# PIC32CK1025GC00064 device description
Architecture: CORTEX-M33; Family: PIC32CK; Series: PIC32CKGC00
Registers are 32-bit, read-write, reset 0x0 unless marked. A register's access mark holds for its fields unless they carry their own. Offsets are from the block's base; [hi:lo] are bit positions; lines under a group give offsets from that group; {n}, {i} and the like mark numbered series; <NAME> marks a mode.

## DWT — Data Watchpoint and Trace
Instances: DWT 0xE0001000
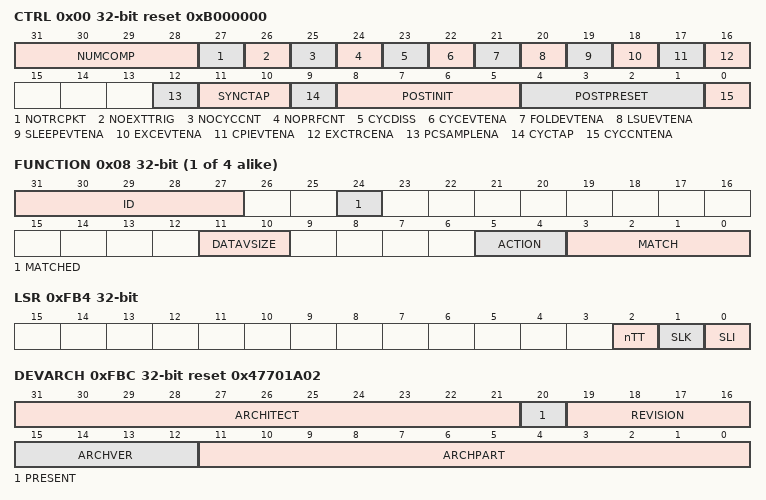
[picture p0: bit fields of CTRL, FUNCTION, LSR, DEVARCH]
0x00 CTRL reset 0xB000000 — DWT Control Register
  [31:28] NUMCOMP — Number of comparators
  [27] NOTRCPKT — No trace packets
  [26] NOEXTTRIG — No external triggers
  [25] NOCYCCNT — No cycle count
  [24] NOPRFCNT — No profile counters
  [23] CYCDISS — Cycle counter disabled secure
  [22] CYCEVTENA — Cycle event enable
  [21] FOLDEVTENA — Fold event enable
  [20] LSUEVTENA — LSU event enable
  [19] SLEEPEVTENA — Sleep event enable
  [18] EXCEVTENA — Exception event enable
  [17] CPIEVTENA — CPI event enable
  [16] EXCTRCENA — Exception trace enable
  [12] PCSAMPLENA — PC sample enable
  [11:10] SYNCTAP — Synchronization tap
  [9] CYCTAP — Cycle count tap
  [8:5] POSTINIT — POSTCNT initial
  [4:1] POSTPRESET — POSTCNT preset
  [0] CYCCNTENA — CYCCNT enable
0x04 CYCCNT reset not defined — DWT Cycle Count Register
  [31:0] CYCCNT — Incrementing cycle counter value
0x08 CPICNT reset not defined — DWT CPI Count Register
  [7:0] CPICNT — Base instruction overhead counter
0x0C EXCCNT reset not defined — DWT Exception Overhead Count Register
  [7:0] EXCCNT — Exception overhead counter
0x10 SLEEPCNT reset not defined — DWT Sleep Count Register
  [7:0] SLEEPCNT — Sleep counter
0x14 LSUCNT reset not defined — DWT LSU Count Register
  [7:0] LSUCNT — Load-store overhead counter
0x18 FOLDCNT reset not defined — DWT Folded Instruction Count Register
  [7:0] FOLDCNT — Folded instruction counter
0x1C PCSR ro reset not defined — DWT Program Counter Sample Register
  [31:0] EIASAMPLE — Executed instruction address sample
{0x20+0x10*i} COMPARATOR[{i}] (i=0..3) group
  0x00 COMP reset not defined — DWT Comparator Register n
    [31:0] VALUE — Cycle/PC/data value or data address
  0x08 FUNCTION reset not defined — DWT Function Register x
    [31:27] ID — Identify capability
    [24] MATCHED — Comparator matched
    [11:10] DATAVSIZE — Data value size
    [5:4] ACTION — Action on match
    [3:0] MATCH — Match type
0xFB0 LAR wo reset not defined — DWT Software Lock Access Register
  [31:0] KEY — Lock access control
    0xC5ACCE55=UNLOCK (Unlock key value)
0xFB4 LSR ro reset not defined — DWT Software Lock Status Register
  [2] nTT — Not thirty-two bit
  [1] SLK — Software Lock status
  [0] SLI — Software Lock implemented
0xFBC DEVARCH ro reset 0x47701A02 — DWT Device Architecture Register
  [31:21] ARCHITECT
  [20] PRESENT — DEVARCH Present
  [19:16] REVISION
  [15:12] ARCHVER — Architecture Version
  [11:0] ARCHPART — Architecture Part
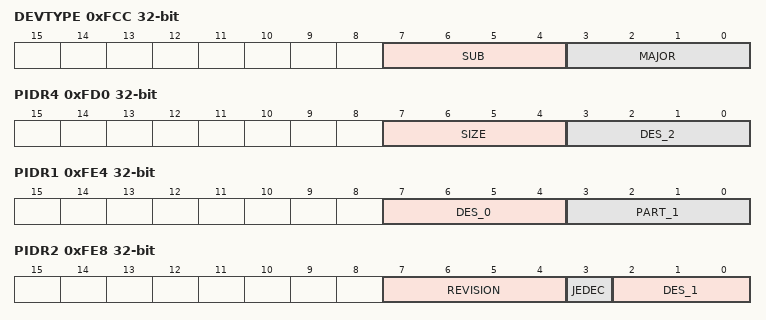
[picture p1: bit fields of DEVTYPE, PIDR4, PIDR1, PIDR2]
0xFCC DEVTYPE ro — DWT Device Type Register
  [7:4] SUB — Sub-type
  [3:0] MAJOR — Major type
0xFD0 PIDR4 ro reset not defined — DWT Peripheral Identification Register 4
  [7:4] SIZE — 4KB count
  [3:0] DES_2 — JEP106 continuation code
{0xFC0+4i} PIDR{i} ro (i=5..7) — DWT Peripheral Identification Register {i}
0xFE0 PIDR0 ro reset not defined — DWT Peripheral Identification Register 0
  [7:0] PART_0 — Part number bits[7:0]
0xFE4 PIDR1 ro reset not defined — DWT Peripheral Identification Register 1
  [7:4] DES_0 — JEP106 identification code bits [3:0]
  [3:0] PART_1 — Part number bits[11:8]
0xFE8 PIDR2 ro reset not defined — DWT Peripheral Identification Register 2
  [7:4] REVISION — Component revision
  [3] JEDEC — JEDEC assignee value is used
  [2:0] DES_1 — JEP106 identification code bits[6:4]
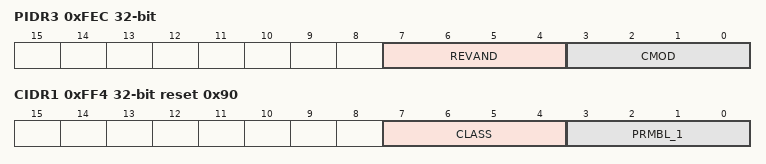
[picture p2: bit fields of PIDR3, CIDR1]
0xFEC PIDR3 ro reset not defined — DWT Peripheral Identification Register 3
  [7:4] REVAND
  [3:0] CMOD — Customer Modified
0xFF0 CIDR0 ro reset 0xD — DWT Component Identification Register 0
  [7:0] PRMBL_0 — CoreSight component identification preamble
0xFF4 CIDR1 ro reset 0x90 — DWT Component Identification Register 1
  [7:4] CLASS — CoreSight component class
  [3:0] PRMBL_1 — CoreSight component identification preamble
0xFF8 CIDR2 ro reset 0x5 — DWT Component Identification Register 2
  [7:0] PRMBL_2 — CoreSight component identification preamble
0xFFC CIDR3 ro reset 0xB1 — DWT Component Identification Register 3
  [7:0] PRMBL_3 — CoreSight component identification preamble

## ITM — Instrumentation Macrocell
Instances: ITM 0xE0000000
Registers as DWT (with DWT read as ITM), without CTRL, CYCCNT, CPICNT, EXCCNT, SLEEPCNT, LSUCNT, FOLDCNT, PCSR, COMPARATOR; these are added or differ:
{0x0+4i} STIM[{i}] (i=0..255) reset not defined — ITM Stimulus Port Register n
  [1] DISABLED <DEFAULT> — Stimulus port enabled
  [0] FIFOREADY <DEFAULT> — Stimulus port can accept data
  [31:0] STIMULUS <WRITE> — Stimulus data
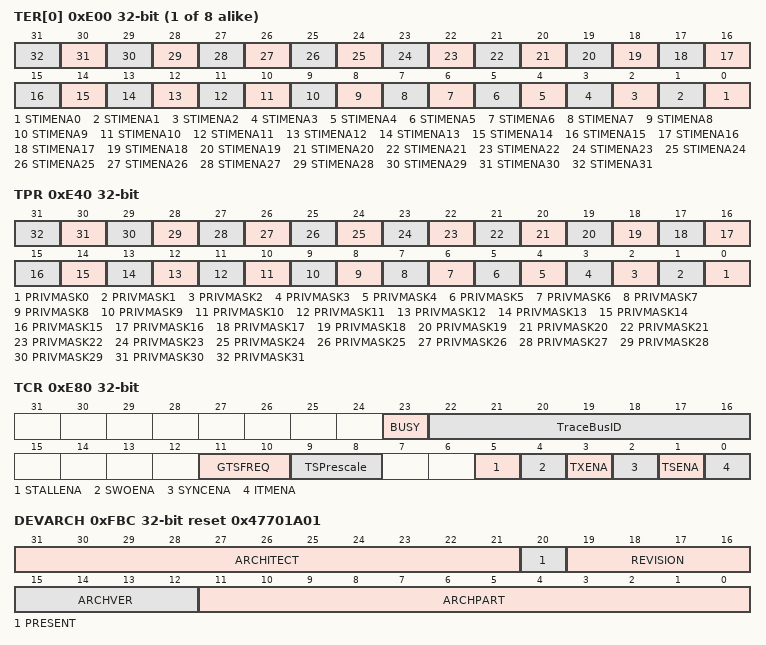
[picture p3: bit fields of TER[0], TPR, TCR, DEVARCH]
{0xE00+4i} TER[{i}] (i=0..7) reset not defined — ITM Trace Enable Register n
  [n] STIMENA{n} (n=0..31) — Stimulus port {n} enabled
0xE40 TPR reset not defined — ITM Trace Privilege Register
  [n] PRIVMASK{n} (n=0..31) — Privilege mask for stimulus port byte {n}
0xE80 TCR reset not defined — ITM Trace Control Register
  [23] BUSY — ITM busy
  [22:16] TraceBusID — Trace bus identity
  [11:10] GTSFREQ — Global timestamp frequency
  [9:8] TSPrescale — Timestamp prescale
  [5] STALLENA — Stall enable
  [4] SWOENA — SWO enable
  [3] TXENA — Transmit enable
  [2] SYNCENA — Synchronization enable
  [1] TSENA — Timestamp enable
  [0] ITMENA — ITM enable
0xFBC DEVARCH ro reset 0x47701A01 — ITM Device Architecture Register
  [31:21] ARCHITECT
  [20] PRESENT — DEVARCH Present
  [19:16] REVISION
  [15:12] ARCHVER — Architecture Version
  [11:0] ARCHPART — Architecture Part
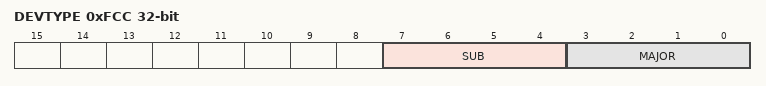
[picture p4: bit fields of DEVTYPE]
0xFCC DEVTYPE ro reset not defined — ITM Device Type Register
  [7:4] SUB — Sub-type
  [3:0] MAJOR — Major type

## TPIU — Trace Port Interface Unit
Instances: TPIU 0xE0040000
Registers as ITM (with ITM read as TPIU), without STIM, TER, TPR, TCR, DEVARCH; these are added or differ:
0x00 SSPSR reset not defined — TPIU Supported Parallel Port Sizes Register
  [31:0] SWIDTH — Supported widths - 1
0x04 CSPSR reset not defined — TPIU Current Parallel Port Sizes Register
  [31:0] CWIDTH — Current parallel trace port widthi - 1
0x10 ACPR reset not defined — TPIU Asynchronous Clock Prescaler Register
  [15:0] SWOSCALER — SWO baud rate prescaler
0xF0 SPPR reset not defined — TPIU Selected Pin Protocol Register
  [1:0] TXMODE
    0=PARALLEL (Parallel trace port mode); 1=MAN (Asynchronous SWO, using Manchester encoding); 2=NRZ (Asynchronous SWO, using NRZ encoding)
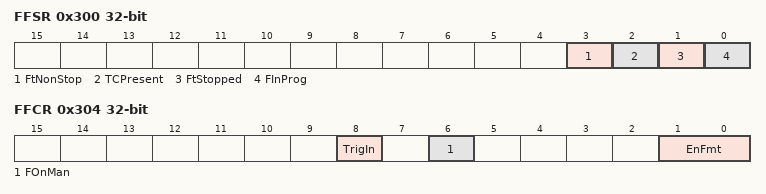
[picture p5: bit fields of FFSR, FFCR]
0x300 FFSR ro reset not defined — TPIU Formatter and Flush Status Register
  [3] FtNonStop — Non-stop formatter
  [2] TCPresent — TRACECTL pin is present
  [1] FtStopped — Formatter stopped
  [0] FInProg — Flush in progress
0x304 FFCR — TPIU Formatter and Flush Control Register
  [8] TrigIn — Trigger input asserted
  [6] FOnMan — Flush On Manual
  [1:0] EnFmt — Output formatting mode
    0=BYPASS (Disable formatting); 2=CONT (Continuous formatting and embed triggers and null cycles)
0x308 PSCR reset not defined — TPIU Periodic Synchronization Control Register
  [4:0] PSCount — Periodic Synchronization Count
0xFC8 DEVID ro reset not defined — TPIU Device Identifier Register
  [24] DWTENA

## Notices in the file
Copyright (c) 2021 Microchip Technology Inc.
SPDX-License-Identifier: Apache-2.0
Licensed under the Apache License, Version 2.0 (the "License");
you may not use this file except in compliance with the License.
You may obtain a copy of the License at
http://www.apache.org/licenses/LICENSE-2.0
Unless required by applicable law or agreed to in writing, software
distributed under the License is distributed on an "AS IS" BASIS,
WITHOUT WARRANTIES OR CONDITIONS OF ANY KIND, either express or implied.
See the License for the specific language governing permissions and
limitations under the License.
